AUTOSAR XML (schema 4-2-2)
package /ServiceApplTemplate/SwComponentTypes
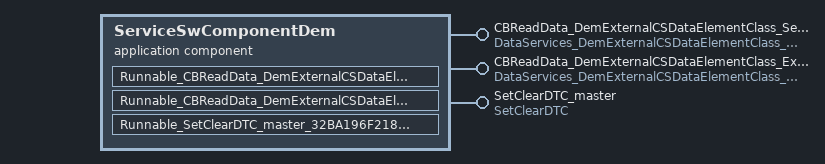
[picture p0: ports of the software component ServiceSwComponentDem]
  application sw component type ServiceSwComponentDem
    provide port CBReadData_DemExternalCSDataElementClass_Session: provided-interface=DataServices_DemExternalCSDataElementClass_Session
    provide port CBReadData_DemExternalCSDataElementClass_ExtDataRec_0x01: provided-interface=DataServices_DemExternalCSDataElementClass_ExtDataRec_0x01
    provide port SetClearDTC_master: provided-interface=SetClearDTC
    behavior ServiceSwComponentDem_IB: handle-termination-and-restart=NO-SUPPORT
      operation invoked event OIE_CBReadData_DemExternalCSDataElementClass_Session_922F0552F856FF32289CE769C88CFC68: start-on-event=Runnable_CBReadData_DemExternalCSDataElementClass_Session_922F0552F856FF32289CE769C88CFC68, operation=CBReadData_DemExternalCSDataElementClass_Session.ReadData
      operation invoked event OIE_CBReadData_DemExternalCSDataElementClass_ExtDataRec_0x01_E3772ED4B9F02DB583EC5F65B2C620FF: start-on-event=Runnable_CBReadData_DemExternalCSDataElementClass_ExtDataRec_0x01_E3772ED4B9F02DB583EC5F65B2C620FF, operation=CBReadData_DemExternalCSDataElementClass_ExtDataRec_0x01.ReadData
      operation invoked event OIE_SetClearDTC_master_32BA196F218C476EBF9AFBFACCD52A0B: start-on-event=Runnable_SetClearDTC_master_32BA196F218C476EBF9AFBFACCD52A0B, operation=SetClearDTC_master.SetClearDTC
      runnable Runnable_CBReadData_DemExternalCSDataElementClass_Session_922F0552F856FF32289CE769C88CFC68: symbol=ServiceSwComponentDem_CBReadData_DemExternalCSDataElementClass_Session_ReadData
      runnable Runnable_CBReadData_DemExternalCSDataElementClass_ExtDataRec_0x01_E3772ED4B9F02DB583EC5F65B2C620FF: symbol=ServiceSwComponentDem_CBReadData_DemExternalCSDataElementClass_ExtDataRec_0x01_ReadData
      runnable Runnable_SetClearDTC_master_32BA196F218C476EBF9AFBFACCD52A0B: symbol=ServiceSwComponentDem_SetClearDTC_master_SetClearDTC
  swc implementation ServiceSwComponentDem_Impl: programming-language=C, sw-version=1.0.0, vendor-id=1, behavior=ServiceSwComponentDem_IB
    code-descriptors:
      code CodeDescriptor: artifact-descriptors=autosar-engineering-object={short-label=EngObject, category=SWSRC}
    resource consumption ResourceConsumption
      memory section Code: sw-addrmethod=CODE, symbol=CODE
package /DemoApplication/SwComponentTypes
  composition sw component type TopLevelComposition
    component ServiceSwComponentDem: type=ServiceSwComponentDem
    connect ServiceSwComponentDem.CBReadData_DemExternalCSDataElementClass_Session -> Dem_Prototype.CBReadData_DemExternalCSDataElementClass_Session
    connect ServiceSwComponentDem.CBReadData_DemExternalCSDataElementClass_ExtDataRec_0x01 -> Dem_Prototype.CBReadData_DemExternalCSDataElementClass_ExtDataRec_0x01
    connect ServiceSwComponentDem.SetClearDTC_master -> Dem_Prototype.SetClearDTC_master
package /CanSystem
  system CanSystem
    system mapping ServiceSwComponentDemSystemMappings
      sw-mappings:
        swc to ecu mapping ServiceSwComponentDemSwcToEcuMapping: component=TopLevelComposition.ServiceSwComponentDem, ecu-instance=EcuTestNode
